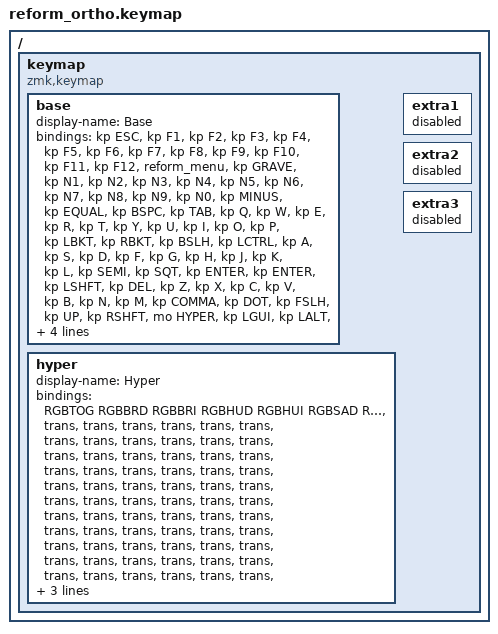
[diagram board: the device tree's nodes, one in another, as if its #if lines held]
/*
  SPDX-License-Identifier: GPL-3.0-or-later
  Copyright 2026 Gordon Q
*/

#include <behaviors.dtsi>
#if CONFIG_MNT_REFORM_MODE == 0 /* MNT_REFORM_MODE_STANDALONE */
#include <behaviors/reform_menu_standalone.dtsi>
#else
#include <behaviors/reform_menu.dtsi>
#endif
#include <behaviors/reform_sysctrl.dtsi>
#include <dt-bindings/zmk/keys.h>
#include <dt-bindings/zmk/mouse.h>
#include <dt-bindings/zmk/rgb.h>

#define BASE  0
#define HYPER 1

#define RGBTOG  &rgb_ug RGB_TOG
#define RGBHUI  &rgb_ug RGB_HUI
#define RGBHUD  &rgb_ug RGB_HUD
#define RGBSAI  &rgb_ug RGB_SAI
#define RGBSAD  &rgb_ug RGB_SAD
#define RGBBRI  &rgb_ug RGB_BRI
#define RGBBRD  &rgb_ug RGB_BRD
#define RGBEFF  &rgb_ug RGB_EFF


// ---------- Reform Ortho key switch positions ----------
//
// 14x6 grid, a gap between columns 7 and 8 holds the LEDs.
// Position = row * 14 + column.
//
// ESC     F1    F2    F3    F4    F5    F6   |  F7    F8    F9    F10   F11   F12   CIRCLE
// GRAVE   1     2     3     4     5     6    |  7     8     9     0     MINUS EQUAL BSPC
// TAB     Q     W     E     R     T     Y    |  U     I     O     P     LBRC  RBRC  BSLS
// LCTRL   A     S     D     F     G     H    |  J     K     L     SCLN  QUOTE ENTER ENTER
// LSFT    DEL   Z     X     C     V     B    |  N     M     COMMA DOT   SLASH UP    RSFT
// HYPER   LGUI  LALT  SPACE SPACE SPACE LCLK |  RCLK  SPACE RALT  RCTL  LEFT  DOWN  RIGHT


/ {
    keymap {
        compatible = "zmk,keymap";

        base {
            // Layer 0 BASE
            display-name = "Base";
            bindings = <
                &kp ESC       &kp F1        &kp F2        &kp F3        &kp F4        &kp F5        &kp F6        &kp F7        &kp F8        &kp F9        &kp F10       &kp F11       &kp F12       &reform_menu
                &kp GRAVE     &kp N1        &kp N2        &kp N3        &kp N4        &kp N5        &kp N6        &kp N7        &kp N8        &kp N9        &kp N0        &kp MINUS     &kp EQUAL     &kp BSPC
                &kp TAB       &kp Q         &kp W         &kp E         &kp R         &kp T         &kp Y         &kp U         &kp I         &kp O         &kp P         &kp LBKT      &kp RBKT      &kp BSLH
                &kp LCTRL     &kp A         &kp S         &kp D         &kp F         &kp G         &kp H         &kp J         &kp K         &kp L         &kp SEMI      &kp SQT       &kp ENTER     &kp ENTER
                &kp LSHFT     &kp DEL       &kp Z         &kp X         &kp C         &kp V         &kp B         &kp N         &kp M         &kp COMMA     &kp DOT       &kp FSLH      &kp UP        &kp RSHFT
                &mo HYPER     &kp LGUI      &kp LALT      &kp SPACE     &kp SPACE     &kp SPACE     &mkp LCLK     &mkp RCLK     &kp SPACE     &kp RALT      &kp RCTRL     &kp LEFT      &kp DOWN      &kp RIGHT
#if CONFIG_MNT_REFORM_MODE == 2 /* MNT_REFORM_MODE_NEXT */
                &mkp LCLK &mkp MCLK &mkp RCLK
#endif
            >;
        };

        hyper {
            // Layer 1 HYPER
            display-name = "Hyper";
            bindings = <
                RGBTOG        RGBBRD        RGBBRI        RGBHUD        RGBHUI        RGBSAD        RGBSAI        RGBEFF        &trans        &trans        &trans        &trans        &trans        &trans
                &trans        &trans        &trans        &trans        &trans        &trans        &trans        &trans        &trans        &trans        &trans        &trans        &trans        &trans
                &trans        &trans        &trans        &trans        &trans        &trans        &trans        &trans        &trans        &trans        &trans        &trans        &trans        &trans
                &trans        &trans        &trans        &trans        &trans        &trans        &trans        &trans        &trans        &trans        &trans        &trans        &trans        &trans
                &trans        &trans        &trans        &trans        &trans        &trans        &trans        &trans        &trans        &trans        &trans        &trans        &trans        &trans
                &trans        &trans        &trans        &trans        &trans        &trans        &mkp MCLK     &trans        &trans        &trans        &trans        &trans        &trans        &trans
#if CONFIG_MNT_REFORM_MODE == 2 /* MNT_REFORM_MODE_NEXT */
                &trans    &trans    &trans
#endif
            >;
        };

        extra1 {
            status = "reserved";
        };

        extra2 {
            status = "reserved";
        };

        extra3 {
            status = "reserved";
        };
    };
};
